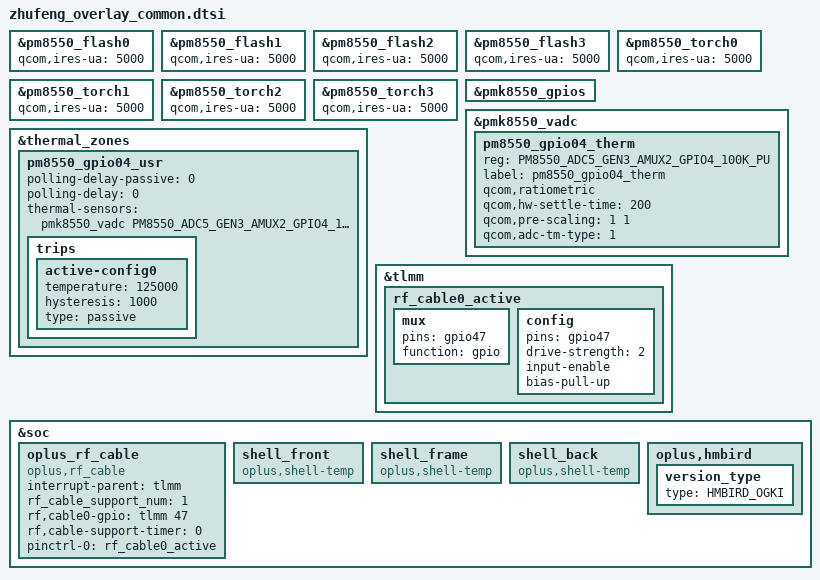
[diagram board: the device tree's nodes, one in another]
&pm8550_flash0 {
	qcom,ires-ua = <5000>;
};

&pm8550_flash1 {
	qcom,ires-ua = <5000>;
};

&pm8550_flash2 {
	qcom,ires-ua = <5000>;
};

&pm8550_flash3 {
	qcom,ires-ua = <5000>;
};

&pm8550_torch0 {
	qcom,ires-ua = <5000>;
};

&pm8550_torch1 {
	qcom,ires-ua = <5000>;
};

&pm8550_torch2 {
	qcom,ires-ua = <5000>;
};

&pm8550_torch3 {
	qcom,ires-ua = <5000>;
};

&pmk8550_gpios {
	/delete-property/ pinctrl-0;
	/delete-property/ pinctrl-names;
	/delete-node/ alt_sleep_clk;
};

&pmk8550_vadc {
    pm8550_gpio04_therm {
        reg = <PM8550_ADC5_GEN3_AMUX2_GPIO4_100K_PU>;
        label = "pm8550_gpio04_therm";
        qcom,ratiometric;
        qcom,hw-settle-time = <200>;
        qcom,pre-scaling = <1 1>;
        qcom,adc-tm-type = <1>;
    };
};

&thermal_zones {
    pm8550_gpio04_usr {
        polling-delay-passive = <0>;
        polling-delay = <0>;
        thermal-sensors = <&pmk8550_vadc PM8550_ADC5_GEN3_AMUX2_GPIO4_100K_PU>;
        trips {
            active-config0 {
                temperature = <125000>;
                hysteresis = <1000>;
                type = "passive";
            };
        };
    };
};

&tlmm {
	//#ifdef OPLUS_FEATURE_RF_CABLE_DETECT
	rf_cable0_active: rf_cable0_active {
		mux {
			pins = "gpio47";
			function = "gpio";
		};
		config {
			pins = "gpio47";
			drive-strength = <2>;
			input-enable;
			bias-pull-up;
		};
	};
	//#endif /* OPLUS_FEATURE_RF_CABLE_DETECT */
};

&soc {
	//#ifdef OPLUS_FEATURE_RF_CABLE_DETECT
	oplus_rf_cable {
		compatible = "oplus,rf_cable";
		interrupt-parent = <&tlmm>;
		rf_cable_support_num = <1>;
		rf,cable0-gpio = <&tlmm 47 0>;
		rf,cable-support-timer = <0>;
		pinctrl-names = "rf_cable_active";
		pinctrl-0 = <&rf_cable0_active>;
	};
	//#endif /* OPLUS_FEATURE_RF_CABLE_DETECT */

	//#ifdef OPLUS_FEATURE_THERMAL_HORAE
	shell_front {
		compatible = "oplus,shell-temp";
	};

	shell_frame {
		compatible = "oplus,shell-temp";
	};

	shell_back {
		compatible = "oplus,shell-temp";
	};
	//#endif /* OPLUS_FEATURE_THERMAL_HORAE */

	//#ifdef CONFIG_HMBIRD_SCHED
	oplus,hmbird {
		version_type {
			type = "HMBIRD_OGKI";
		};
	};
	//#endif /* CONFIG_HMBIRD_SCHED */
};
